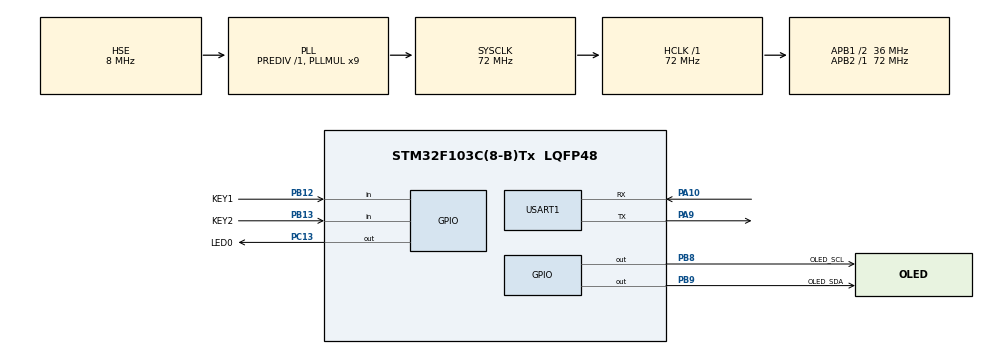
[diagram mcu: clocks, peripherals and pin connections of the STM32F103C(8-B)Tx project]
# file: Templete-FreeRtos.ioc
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Dma.Request0=USART1_RX
Dma.Request1=USART1_TX
Dma.USART1_RX.0.Direction=DMA_PERIPH_TO_MEMORY
Dma.USART1_RX.0.Instance=DMA1_Channel5
Dma.USART1_RX.0.MemDataAlignment=DMA_MDATAALIGN_BYTE
Dma.USART1_RX.0.MemInc=DMA_MINC_ENABLE
Dma.USART1_RX.0.Mode=DMA_NORMAL
Dma.USART1_RX.0.PeriphDataAlignment=DMA_PDATAALIGN_BYTE
Dma.USART1_RX.0.PeriphInc=DMA_PINC_DISABLE
Dma.USART1_RX.0.Priority=DMA_PRIORITY_LOW
Dma.USART1_TX.1.Direction=DMA_MEMORY_TO_PERIPH
Dma.USART1_TX.1.Instance=DMA1_Channel4
Dma.USART1_TX.1.MemDataAlignment=DMA_MDATAALIGN_BYTE
Dma.USART1_TX.1.MemInc=DMA_MINC_ENABLE
Dma.USART1_TX.1.Mode=DMA_NORMAL
Dma.USART1_TX.1.PeriphDataAlignment=DMA_PDATAALIGN_BYTE
Dma.USART1_TX.1.PeriphInc=DMA_PINC_DISABLE
Dma.USART1_TX.1.Priority=DMA_PRIORITY_LOW
FREERTOS.BinarySemaphores01=myBinarySem01,Dynamic,NULL
FREERTOS.CountingSemaphores01=myCountingSem01,4,Dynamic,NULL
FREERTOS.Queues01=myQueue01,1,uint8_t,0,Dynamic,NULL,NULL
FREERTOS.Tasks01=defaultTask,24,128,StartDefaultTask,Default,NULL,Dynamic,NULL,NULL;myTask01,24,128,StartTask01,Default,NULL,Dynamic,NULL,NULL;myTask02,24,128,StartTask02,Default,NULL,Dynamic,NULL,NULL;myTask03,24,128,StartTask03,Default,NULL,Dynamic,NULL,NULL
Mcu.Family=STM32F1
Mcu.Name=STM32F103C(8-B)Tx
Mcu.Package=LQFP48
NVIC.DMA1_Channel4_IRQn=true\:5\:0\:false\:false\:true\:true\:false\:true\:true
NVIC.DMA1_Channel5_IRQn=true\:5\:0\:false\:false\:true\:true\:false\:true\:true
NVIC.PriorityGroup=NVIC_PRIORITYGROUP_4
NVIC.TIM1_UP_IRQn=true\:15\:0\:false\:false\:true\:false\:false\:true\:true
NVIC.TIM2_IRQn=true\:5\:0\:false\:false\:true\:true\:true\:true\:true
NVIC.TimeBase=TIM1_UP_IRQn
NVIC.TimeBaseIP=TIM1
NVIC.USART1_IRQn=true\:5\:0\:false\:false\:true\:true\:true\:true\:true
PA10.Mode=Asynchronous
PA10.Signal=USART1_RX
PA13.Mode=Serial_Wire
PA13.Signal=SYS_JTMS-SWDIO
PA14.Mode=Serial_Wire
PA14.Signal=SYS_JTCK-SWCLK
PA9.Mode=Asynchronous
PA9.Signal=USART1_TX
PB12.GPIO_Label=KEY1
PB12.GPIO_PuPd=GPIO_PULLUP
PB12.Signal=GPIO_Input
PB13.GPIO_Label=KEY2
PB13.GPIO_PuPd=GPIO_PULLUP
PB13.Signal=GPIO_Input
PB8.GPIO_Label=OLED_SCL
PB8.GPIO_Speed=GPIO_SPEED_FREQ_HIGH
PB8.Signal=GPIO_Output
PB9.GPIO_Label=OLED_SDA
PB9.GPIO_Speed=GPIO_SPEED_FREQ_HIGH
PB9.Signal=GPIO_Output
PC13-TAMPER-RTC.GPIO_Label=LED0
PC13-TAMPER-RTC.PinState=GPIO_PIN_SET
PC13-TAMPER-RTC.Signal=GPIO_Output
PD0-OSC_IN.Mode=HSE-External-Oscillator
PD0-OSC_IN.Signal=RCC_OSC_IN
PD1-OSC_OUT.Mode=HSE-External-Oscillator
PD1-OSC_OUT.Signal=RCC_OSC_OUT
ProjectManager.HeapSize=0x200
ProjectManager.StackSize=0x400
ProjectManager.TargetToolchain=MDK-ARM V5.32
RCC.AHBFreq_Value=72000000
RCC.APB1CLKDivider=RCC_HCLK_DIV2
RCC.APB1Freq_Value=36000000
RCC.APB1TimFreq_Value=72000000
RCC.APB2Freq_Value=72000000
RCC.APB2TimFreq_Value=72000000
RCC.HCLKFreq_Value=72000000
RCC.PLLMUL=RCC_PLL_MUL9
RCC.PLLSourceVirtual=RCC_PLLSOURCE_HSE
RCC.SYSCLKFreq_VALUE=72000000
RCC.SYSCLKSource=RCC_SYSCLKSOURCE_PLLCLK
RCC.USBFreq_Value=72000000
TIM2.AutoReloadPreload=TIM_AUTORELOAD_PRELOAD_ENABLE
TIM2.Period=1000-1
TIM2.Prescaler=72-1
USART1.VirtualMode=VM_ASYNC
VP_FREERTOS_VS_CMSIS_V2.Mode=CMSIS_V2
VP_SYS_VS_tim1.Mode=TIM1
VP_TIM2_VS_ClockSourceINT.Mode=Internal
board=custom

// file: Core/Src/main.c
/* USER CODE BEGIN Header */
/**
  ******************************************************************************
  * @file           : main.c
  * @brief          : Main program body
  ******************************************************************************
  * @attention
  *
  * Copyright (c) 2026 STMicroelectronics.
  * All rights reserved.
  *
  * This software is licensed under terms that can be found in the LICENSE file
  * in the root directory of this software component.
  * If no LICENSE file comes with this software, it is provided AS-IS.
  *
  ******************************************************************************
  */
/* USER CODE END Header */
#include "main.h"
#include "cmsis_os.h"
#include "dma.h"
#include "tim.h"
#include "usart.h"
#include "gpio.h"

/* USER CODE BEGIN Includes */
#include "MyTask.h"
/* USER CODE END Includes */

void SystemClock_Config(void);
void MX_FREERTOS_Init(void);

int main(void)
{

  /* MCU Configuration--------------------------------------------------------*/

  /* Reset of all peripherals, Initializes the Flash interface and the Systick. */
  HAL_Init();

  /* Configure the system clock */
  SystemClock_Config();

  /* Initialize all configured peripherals */
  MX_GPIO_Init();
  MX_DMA_Init();
  MX_USART1_UART_Init();
  MX_TIM2_Init();

  /* Init scheduler */
  osKernelInitialize();  /* Call init function for freertos objects (in freertos.c) */
  MX_FREERTOS_Init();

  /* Start scheduler */
  osKernelStart();

  /* We should never get here as control is now taken by the scheduler */
  /* Infinite loop */
  while (1)
  {

  }
}

void SystemClock_Config(void)
{
  RCC_OscInitTypeDef RCC_OscInitStruct = {0};
  RCC_ClkInitTypeDef RCC_ClkInitStruct = {0};

  /** Initializes the RCC Oscillators according to the specified parameters
  * in the RCC_OscInitTypeDef structure.
  */
  RCC_OscInitStruct.OscillatorType = RCC_OSCILLATORTYPE_HSE;
  RCC_OscInitStruct.HSEState = RCC_HSE_ON;
  RCC_OscInitStruct.HSEPredivValue = RCC_HSE_PREDIV_DIV1;
  RCC_OscInitStruct.HSIState = RCC_HSI_ON;
  RCC_OscInitStruct.PLL.PLLState = RCC_PLL_ON;
  RCC_OscInitStruct.PLL.PLLSource = RCC_PLLSOURCE_HSE;
  RCC_OscInitStruct.PLL.PLLMUL = RCC_PLL_MUL9;
  if (HAL_RCC_OscConfig(&RCC_OscInitStruct) != HAL_OK)
  {
    Error_Handler();
  }

  /** Initializes the CPU, AHB and APB buses clocks
  */
  RCC_ClkInitStruct.ClockType = RCC_CLOCKTYPE_HCLK|RCC_CLOCKTYPE_SYSCLK
                              |RCC_CLOCKTYPE_PCLK1|RCC_CLOCKTYPE_PCLK2;
  RCC_ClkInitStruct.SYSCLKSource = RCC_SYSCLKSOURCE_PLLCLK;
  RCC_ClkInitStruct.AHBCLKDivider = RCC_SYSCLK_DIV1;
  RCC_ClkInitStruct.APB1CLKDivider = RCC_HCLK_DIV2;
  RCC_ClkInitStruct.APB2CLKDivider = RCC_HCLK_DIV1;

  if (HAL_RCC_ClockConfig(&RCC_ClkInitStruct, FLASH_LATENCY_2) != HAL_OK)
  {
    Error_Handler();
  }
}

void HAL_TIM_PeriodElapsedCallback(TIM_HandleTypeDef *htim)
{
  if (htim->Instance == TIM1) {
    HAL_IncTick();
  }
  /* USER CODE BEGIN Callback 1 */
	tim2_cb(htim) ;
  /* USER CODE END Callback 1 */
}

void Error_Handler(void)
{
  __disable_irq();
  while (1)
  {
  }
}

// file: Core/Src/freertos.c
/* USER CODE BEGIN Header */
/**
  ******************************************************************************
  * File Name          : freertos.c
  * Description        : Code for freertos applications
  ******************************************************************************
  * @attention
  *
  * Copyright (c) 2026 STMicroelectronics.
  * All rights reserved.
  *
  * This software is licensed under terms that can be found in the LICENSE file
  * in the root directory of this software component.
  * If no LICENSE file comes with this software, it is provided AS-IS.
  *
  ******************************************************************************
  */
/* USER CODE END Header */

#include "FreeRTOS.h"
#include "task.h"
#include "main.h"
#include "cmsis_os.h"

/* USER CODE BEGIN Includes */
#include "MyTask.h"	// 用户初始化和任务入口
/* USER CODE END Includes */

/* Definitions for defaultTask */
osThreadId_t defaultTaskHandle;
const osThreadAttr_t defaultTask_attributes = {
  .name = "defaultTask",
  .stack_size = 128 * 4,
  .priority = (osPriority_t) osPriorityNormal,
};
/* Definitions for myTask01 */
osThreadId_t myTask01Handle;
const osThreadAttr_t myTask01_attributes = {
  .name = "myTask01",
  .stack_size = 128 * 4,
  .priority = (osPriority_t) osPriorityNormal,
};
/* Definitions for myTask02 */
osThreadId_t myTask02Handle;
const osThreadAttr_t myTask02_attributes = {
  .name = "myTask02",
  .stack_size = 128 * 4,
  .priority = (osPriority_t) osPriorityNormal,
};
/* Definitions for myTask03 */
osThreadId_t myTask03Handle;
const osThreadAttr_t myTask03_attributes = {
  .name = "myTask03",
  .stack_size = 128 * 4,
  .priority = (osPriority_t) osPriorityNormal,
};
/* Definitions for myQueue01 */
osMessageQueueId_t myQueue01Handle;
const osMessageQueueAttr_t myQueue01_attributes = {
  .name = "myQueue01"
};
/* Definitions for myBinarySem01 */
osSemaphoreId_t myBinarySem01Handle;
const osSemaphoreAttr_t myBinarySem01_attributes = {
  .name = "myBinarySem01"
};
/* Definitions for myCountingSem01 */
osSemaphoreId_t myCountingSem01Handle;
const osSemaphoreAttr_t myCountingSem01_attributes = {
  .name = "myCountingSem01"
};

void StartDefaultTask(void *argument);
void StartTask01(void *argument);
void StartTask02(void *argument);
void StartTask03(void *argument);

void MX_FREERTOS_Init(void); /* (MISRA C 2004 rule 8.1) */

void MX_FREERTOS_Init(void) {
  /* USER CODE BEGIN Init */

	// 用户初始化
	Initial_ALL() ;

  /* USER CODE END Init */

  /* Create the semaphores(s) */
  /* creation of myBinarySem01 */
  myBinarySem01Handle = osSemaphoreNew(1, 1, &myBinarySem01_attributes);

  /* creation of myCountingSem01 */
  myCountingSem01Handle = osSemaphoreNew(4, 4, &myCountingSem01_attributes);

  /* Create the queue(s) */
  /* creation of myQueue01 */
  myQueue01Handle = osMessageQueueNew (1, sizeof(uint8_t), &myQueue01_attributes);

  /* Create the thread(s) */
  /* creation of defaultTask */
  defaultTaskHandle = osThreadNew(StartDefaultTask, NULL, &defaultTask_attributes);

  /* creation of myTask01 */
  myTask01Handle = osThreadNew(StartTask01, NULL, &myTask01_attributes);

  /* creation of myTask02 */
  myTask02Handle = osThreadNew(StartTask02, NULL, &myTask02_attributes);

  /* creation of myTask03 */
  myTask03Handle = osThreadNew(StartTask03, NULL, &myTask03_attributes);

}

void StartDefaultTask(void *argument)
{
  /* USER CODE BEGIN StartDefaultTask */
  /* Infinite loop */
  for(;;)
  {
		MyTask_default() ;
  }
  /* USER CODE END StartDefaultTask */
}

void StartTask01(void *argument)
{
  /* USER CODE BEGIN StartTask01 */
  /* Infinite loop */
  for(;;)
  {
		MyTask_01() ;
  }
  /* USER CODE END StartTask01 */
}

void StartTask02(void *argument)
{
  /* USER CODE BEGIN StartTask02 */
  /* Infinite loop */
  for(;;)
  {
    MyTask_02() ;
  }
  /* USER CODE END StartTask02 */
}

void StartTask03(void *argument)
{
  /* USER CODE BEGIN StartTask03 */
  /* Infinite loop */
  for(;;)
  {
    MyTask_03() ;
  }
  /* USER CODE END StartTask03 */
}
